# PRU_ICSS_0_CFG_local register map
Vendor: Texas Instruments
Peripheral module from a debugger description file (folder 66AK2G0x_66AK2G1x).
Registers are 32-bit, access per field, reset 0x0 unless marked. A register's access mark holds for its fields unless they carry their own. Offsets are as the file gives them; lines under a group give offsets from that group; [hi:lo] are bit positions; {n}, {i} and the like mark numbered series; 'fields as' and 'values as' point back to an identical list; <NAME> marks a mode.

## PRU_ICSS_0_CFG
0x00 PRUSS_REVID ro reset 0x47000A02
  [31:0] REVISION — TI internal data. Identifies revision of peripheral.
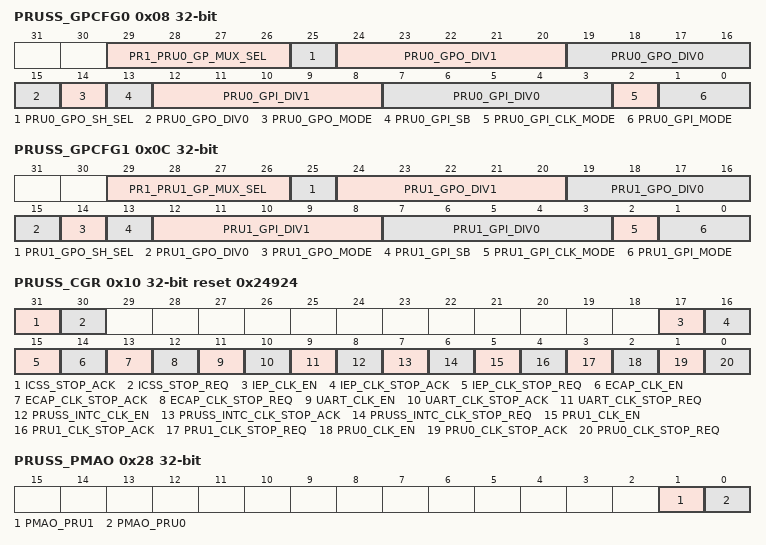
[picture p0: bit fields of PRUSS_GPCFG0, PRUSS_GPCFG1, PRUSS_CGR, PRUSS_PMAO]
0x08 PRUSS_GPCFG0
  [29:26] PR1_PRU0_GP_MUX_SEL rw — Controls the PRU-ICSS wrap mux selection.
  [25] PRU0_GPO_SH_SEL ro — Defines which shadow register is currently getting used for GPO shifting.
  [24:20] PRU0_GPO_DIV1 rw — Divisor value (divide by PRU0_GPO_DIV1 + 1).
  [19:15] PRU0_GPO_DIV0 rw — Divisor value (divide by PRU0_GPO_DIV0 + 1).
  [14] PRU0_GPO_MODE rw — PRU GPO (R30) modes:
  [13] PRU0_GPI_SB rw — Start Bit event for 28-bit shift mode.
  [12:8] PRU0_GPI_DIV1 rw — Divisor value (divide by PRU0_GPI_DIV1 + 1).
  [7:3] PRU0_GPI_DIV0 rw — Divisor value (divide by PRU0_GPI_DIV0 + 1).
  [2] PRU0_GPI_CLK_MODE rw — Parallel 16-bit capture mode clock edge.
  [1:0] PRU0_GPI_MODE rw — PRU GPI (R31) modes:
0x0C PRUSS_GPCFG1
  [29:26] PR1_PRU1_GP_MUX_SEL rw — Controls the PRU-ICSS wrap mux selection.
  [25] PRU1_GPO_SH_SEL ro — Defines which shadow register is currently getting used for GPO shifting.
  [24:20] PRU1_GPO_DIV1 rw — Divisor value (divide by PRU1_GPO_DIV1 + 1).
  [19:15] PRU1_GPO_DIV0 rw — Divisor value (divide by PRU1_GPO_DIV0 + 1).
  [14] PRU1_GPO_MODE rw — PRU GPO (R30) modes:
  [13] PRU1_GPI_SB rw — 28-bit shift mode Start Bit event.
  [12:8] PRU1_GPI_DIV1 rw — Divisor value (divide by PRU1_GPI_DIV1 + 1).
  [7:3] PRU1_GPI_DIV0 rw — Divisor value (divide by PRU1_GPI_DIV0 + 1).
  [2] PRU1_GPI_CLK_MODE rw — Parallel 16-bit capture mode clock edge.
  [1:0] PRU1_GPI_MODE rw — PRU GPI (R31) modes:
0x10 PRUSS_CGR reset 0x24924
  [31] ICSS_STOP_ACK rw — Acknowledgement that ICSS clock can be stopped.
  [30] ICSS_STOP_REQ ro — ICSS request to stop clock.
  [17] IEP_CLK_EN rw — IEP clock enable.
  [16] IEP_CLK_STOP_ACK ro — Acknowledgement that IEP clock can be stopped.
  [15] IEP_CLK_STOP_REQ rw — IEP request to stop clock.
  [14] ECAP_CLK_EN rw — ECAP clock enable.
  [13] ECAP_CLK_STOP_ACK ro — Acknowledgement that ECAP clock can be stopped.
  [12] ECAP_CLK_STOP_REQ rw — ECAP request to stop clock.
  [11] UART_CLK_EN rw — UART clock enable.
  [10] UART_CLK_STOP_ACK ro — Acknowledgement that UART clock can be stopped.
  [9] UART_CLK_STOP_REQ rw — UART request to stop clock.
  [8] PRUSS_INTC_CLK_EN rw — PRUSS_INTC clock enable.
  [7] PRUSS_INTC_CLK_STOP_ACK ro — Acknowledgement that PRUSS_INTC clock can be stopped.
  [6] PRUSS_INTC_CLK_STOP_REQ rw — PRUSS_INTC request to stop clock.
  [5] PRU1_CLK_EN rw — PRU1 clock enable.
  [4] PRU1_CLK_STOP_ACK ro — Acknowledgement that PRU1 clock can be stopped.
  [3] PRU1_CLK_STOP_REQ rw — PRU1 request to stop clock.
  [2] PRU0_CLK_EN rw — PRU0 clock enable.
  [1] PRU0_CLK_STOP_ACK ro — Acknowledgement that PRU0 clock can be stopped.
  [0] PRU0_CLK_STOP_REQ rw — PRU0 request to stop clock.
0x28 PRUSS_PMAO
  [1] PMAO_PRU1 rw — PRU1 Master Port Address Offset Enable.
  [0] PMAO_PRU0 rw — PRU0 Master Port Address Offset Enable.
0x2C PRUSS_MII_RT reset 0x1
  [0] MII_RT_EVENT_EN rw — Enables the MII_RT Events to the PRU-ICSS_INTC.
0x30 PRUSS_IEPCLK
  [0] OCP_EN rw — IEP clock source.
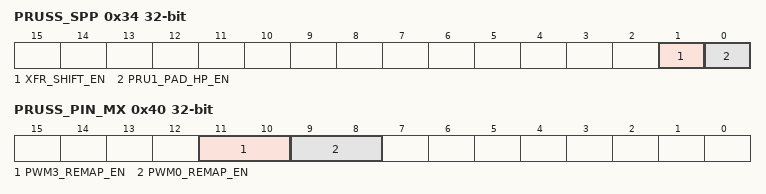
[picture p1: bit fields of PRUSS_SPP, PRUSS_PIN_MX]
0x34 PRUSS_SPP
  [1] XFR_SHIFT_EN rw — Enables XIN XOUT shift functionality. When enabled, R0[4-0] (internal to PRU) defines the 32-bit offset for XIN and XOUT operations with the scratch pad.
  [0] PRU1_PAD_HP_EN rw — Defines which PRU wins write cycle arbitration to a common scratch pad bank. The PRU which has higher priority will always perform the write cycle with no wait states. The lower PRU will get stalled wait states until higher PRU is not performing write cycles. If the lower priority PRU writes to the same byte has the higher priority PRU, then the lower priority PRU will over write the bytes.
0x40 PRUSS_PIN_MX
  [11:10] PWM3_REMAP_EN rw — Remaps the eHRPWM3_SYNCI to a PRU-ICSS Host Interrupt. This bit field is only controlled by PRU-ICSS_0. If enabled, PRU-ICSS Host Interrupt 7 controls eHRPWM3_SYNCI. See for more details about eHRPWM3_SYNCI signal. 0h: Disabled 1h: PRU-ICSS_0 Host Interrupt 7 controls eHRPWM3_SYNCI 2h: PRU-ICSS_1 Host Interrupt 7 controls eHRPWM3_SYNCI 3h: Reserved
  [9:8] PWM0_REMAP_EN rw — Remaps the eHRPWM0_SYNCI to a PRU-ICSS Host Interrupt. This bit field is only controlled by PRU-ICSS_0. If enabled, PRU-ICSS Host Interrupt 6 controls eHRPWM0_SYNCI. See for more details about eHRPWM0_SYNCI signal. 0h: Disabled 1h: PRU-ICSS_0 Host Interrupt 6 controls eHRPWM0_SYNCI 2h: PRU-ICSS_1 Host Interrupt 6 controls eHRPWM0_SYNCI 3h: Reserved
